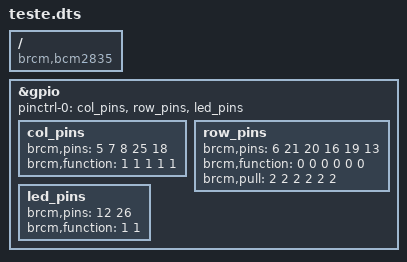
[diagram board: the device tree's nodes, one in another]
/dts-v1/;
/plugin/;

/ {
    compatible = "brcm,bcm2835";

    fragment@0 {
        target = <&gpio>;

        __overlay__ {
            pinctrl-names = "default";
            pinctrl-0 = <&col_pins &row_pins &led_pins>;
        };
    };

    fragment@1 {
        target = <&gpio>;

        __overlay__ {
            col_pins: col_pins {
                brcm,pins = <5 7 8 25 18>;
                brcm,function = <1 1 1 1 1>;
            };
        };
    };

    fragment@2 {
        target = <&gpio>;

        __overlay__ {
            row_pins: row_pins {
                brcm,pins = <6 21 20 16 19 13>;
                brcm,function = <0 0 0 0 0 0>;
                brcm,pull = <2 2 2 2 2 2>;
            };
        };
    };

    fragment@3 {
        target = <&gpio>;

        __overlay__ {
            led_pins: led_pins {
                brcm,pins = <12 26>;
                brcm,function = <1 1>;
            };
        };
    };
};
